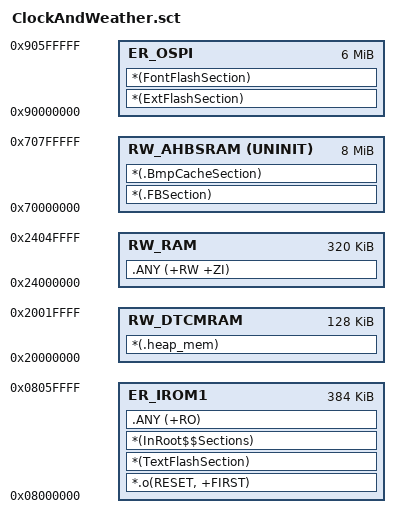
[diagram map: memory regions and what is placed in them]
; *************************************************************
; *** Scatter-Loading Description File generated by uVision ***
; *************************************************************

LR_IROM1 0x08000000 0x60000 {    ; load region size_region

   ER_IROM1 0x08000000 0x60000  {  ; load address = execution address
		*.o(RESET, +FIRST)
        *(TextFlashSection)
        *(InRoot$$Sections)
        .ANY (+RO) 
	}
	 

 RW_DTCMRAM 0x20000000  0x00020000 { 
  *(.heap_mem)
  
  }
  RW_RAM 0x24000000 0x50000 {
   .ANY (+RW +ZI)
  }
  RW_AHBSRAM 0x70000000 UNINIT 0x800000 { ; RW data
  *(.FBSection)
  *(.BmpCacheSection)
  	}  
}

LR_OSPI 0x90000000 0x600000 {    
 ER_OSPI 0x90000000 0x600000  {	
  	*(ExtFlashSection)
	 *(FontFlashSection) 
	}
}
